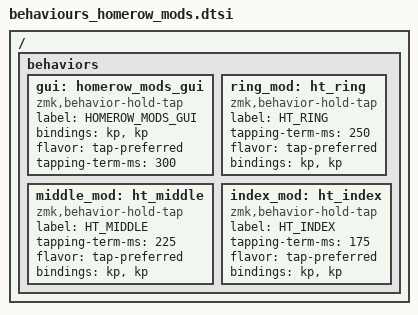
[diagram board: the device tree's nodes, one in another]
// Make sure settings.dtsi is included before this file

#define HM_TAPPING_TERM 300
#define HM_TAPPING_TERM_FAST 200
#define HM_PRIOR_IDLE 150

/ {

    behaviors {
  gui: homerow_mods_gui {
        compatible = "zmk,behavior-hold-tap";
          label = "HOMEROW_MODS_GUI";
          #binding-cells = <2>;
          bindings = <&kp>, <&kp>; 
         flavor = "tap-preferred";
          tapping-term-ms = <300>;

      };

      ring_mod: ht_ring {
        compatible = "zmk,behavior-hold-tap";
          label = "HT_RING";
          #binding-cells = <2>;
          tapping-term-ms = <250>;
          flavor = "tap-preferred";
          bindings = <&kp>, <&kp>;
      };

     middle_mod: ht_middle {
        compatible = "zmk,behavior-hold-tap";
          label = "HT_MIDDLE";
          #binding-cells = <2>;
          tapping-term-ms = <225>;
          flavor = "tap-preferred";
          bindings = <&kp>, <&kp>;
      };

      index_mod: ht_index {
        compatible = "zmk,behavior-hold-tap";
          label = "HT_INDEX";
          #binding-cells = <2>;
          tapping-term-ms = <175>;
          flavor = "tap-preferred";
          bindings = <&kp>, <&kp>;
      };



    };
};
